# ISS_TOP register map
Vendor: Texas Instruments
Peripheral module from a debugger description file (folder omap5430_ES2_PUBLIC).
Registers are 32-bit, access not given, reset 0x0 unless marked. A register's access mark holds for its fields unless they carry their own. Offsets are as the file gives them; lines under a group give offsets from that group; [hi:lo] are bit positions; {n}, {i} and the like mark numbered series; 'fields as' and 'values as' point back to an identical list; <NAME> marks a mode.

## ISS_TOP
0x00 ISS_HL_REVISION ro reset not defined — IP Revision Identifier (X.Y.R) Used by software to track features, bugs, and compatibility
  [31:0] REVISION — IP Revision
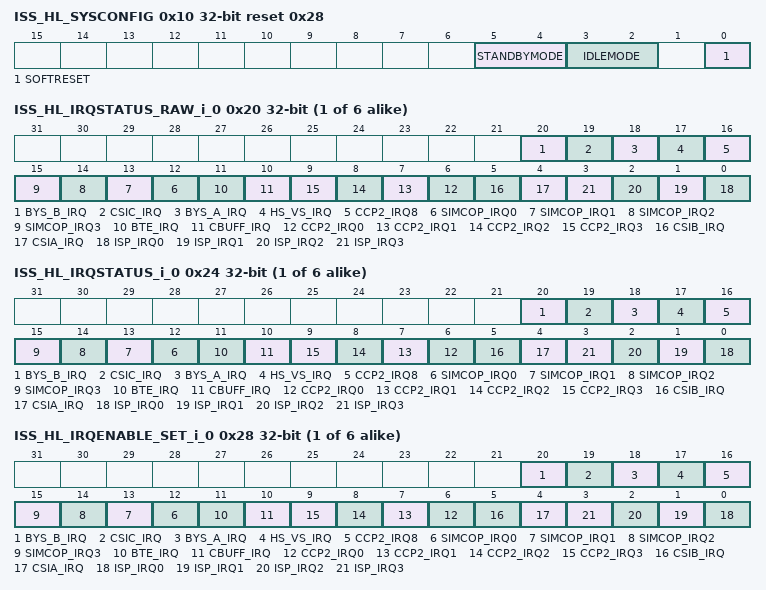
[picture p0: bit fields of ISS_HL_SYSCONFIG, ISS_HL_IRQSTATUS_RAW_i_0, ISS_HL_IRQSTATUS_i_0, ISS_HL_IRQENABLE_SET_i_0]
0x10 ISS_HL_SYSCONFIG access per field reset 0x28 — Clock management configuration
  [5:4] STANDBYMODE rw — Master interface power management, standby/Wait control
    0=FORCE (Force-standby. MStandby is asserted unconditionally.); 1=NO (No-standby. MStandby is never asserted.); 3=SMART2 (Smart-standby Wake up); 2=SMART1 (Smart-standby)
  [3:2] IDLEMODE rw — IDLE protocol configuration
    0=FORCE (Force-idle); 1=NO (No-idle); 3=SMART2 (Smart-idle Wake up); 2=SMART1 (Smart-idle)
  [0] SOFTRESET rw — Software reset.
    0=done (No action); 1=pending (Initiate software reset); 1=pending (Reset (software or other) ongoing); 0=Reset_done,_no_pending_action
{0x20+0x10*i} ISS_HL_IRQSTATUS_RAW_i_{i} access per field (i=0..5) — Per-event raw interrupt status vector, line 0. Raw status is set even if event is not enabled by setting the register.
  [20] BYS_B_IRQ ro — Event generated by BYS_B
    1=pending (Event pending); 0=No event pending
  [19] CSIC_IRQ ro — Event generated by the CSI2_C receiver
    1=pending (Event pending); 0=No event pending
  [18] BYS_A_IRQ ro — Event generated by BYS_A
    1=pending (Event pending); 0=No event pending
  [17] HS_VS_IRQ rw — HS or VS synchronization event. This event is triggered if a rising or falling edge is detected on the HS or VS signal (after the video port mux). The rising or falling edge and the HS or VS signal selection is chosen with the ISS_CTRL[1:0] SYNC_DETECT bit field.
    0=noevent (No action); 1=pending (Set event (debug)); 1=pending (Event pending); 0=No_event_pending
  [16] CCP2_IRQ8 ro — Event generated by the CCP2 receiver
    1=pending (Event pending); 0=No event pending
  [n+12] SIMCOP_IRQ{n} ro (n=0..3) — Event generated by SIMCOP
    1=pending (Event pending); 0=No event pending
  [11] BTE_IRQ ro — Event generated by the burst translation engine
    1=pending (Event pending); 0=No event pending
  [10] CBUFF_IRQ ro — Event generated by the circular buffer
    1=pending (Event pending); 0=No event pending
  [n+6] CCP2_IRQ{n} ro (n=0..3) — Event generated by the CCP2 receiver
    1=pending (Event pending); 0=No event pending
  [5] CSIB_IRQ ro — Event generated by the CSI2_B receiver
    1=pending (Event pending); 0=No event pending
  [4] CSIA_IRQ ro — Event generated by the CSI2_A receiver
    1=pending (Event pending); 0=No event pending
  [n] ISP_IRQ{n} ro (n=0..3) — Combined interrupt event provided by the ISP.
    1=pending (Event pending); 0=No event pending
{0x24+0x10*i} ISS_HL_IRQSTATUS_i_{i} (i=0..5) — Per-event 'enabled' interrupt status vector, line 0. Enabled status is not set unless event is enabled by setting the register.
  [20] BYS_B_IRQ ro — Event generated by BYS_B
    1=pending (Event pending); 0=noevent (No (enabled) event pending)
  [19] CSIC_IRQ ro — Event generated by the CSI2_C receiver
    values as BYS_B_IRQ
  [18] BYS_A_IRQ ro — Event generated by BYS_A
    values as BYS_B_IRQ
  [17] HS_VS_IRQ — HS or VS synchronization event. This event is triggered if a rising or falling edge is detected on the HS or VS signal (after the video port mux). The rising or falling edge and the HS or VS signal selection is chosen with the ISS_CTRL[1:0] SYNC_DETECT bit field. (access RW W1toSet)
    0=noevent (No action); 1=pending (Clear (raw) event); 1=pending (Event pending); 0=No_(enabled)_event_pending
  [16] CCP2_IRQ8 ro — Event generated by the CCP2 receiver
    values as BYS_B_IRQ
  [n+12] SIMCOP_IRQ{n} ro (n=0..3) — Event generated by SIMCOP
    values as BYS_B_IRQ
  [11] BTE_IRQ ro — Event generated by the burst translation engine
    values as BYS_B_IRQ
  [10] CBUFF_IRQ ro — Event generated by the circular buffer
    values as BYS_B_IRQ
  [n+6] CCP2_IRQ{n} ro (n=0..3) — Event generated by the CCP2 receiver
    values as BYS_B_IRQ
  [5] CSIB_IRQ ro — Event generated by the CSI2_B receiver
    values as BYS_B_IRQ
  [4] CSIA_IRQ ro — Event generated by the CSI2_A receiver
    values as BYS_B_IRQ
  [n] ISP_IRQ{n} ro (n=0..3) — Combined interrupt event provided by the ISP.
    values as BYS_B_IRQ
{0x28+0x10*i} ISS_HL_IRQENABLE_SET_i_{i} (i=0..5) — Per-event interrupt enable bit vector. Write 1 to set (enable interrupt). Readout equal to corresponding register bit.
  [20] BYS_B_IRQ — Event generated by BYS_B (access RW W1toSet)
    0=disabled (No action); 1=enabled (Enable interrupt); 1=enabled (Interrupt enabled); 0=Interrupt_disabled_(masked)
  [19] CSIC_IRQ — Event generated by the CSI2_C receiver (access RW W1toSet)
    values as BYS_B_IRQ
  [18] BYS_A_IRQ — Event generated by BYS_A (access RW W1toSet)
    values as BYS_B_IRQ
  [17] HS_VS_IRQ — HS or VS synchronization event. This event is triggered if a rising or falling edge is detected on the HS or VS signal (after the video port mux). The rising or falling edge and the HS or VS signal selection is chosen with the ISS_CTRL[1:0] SYNC_DETECT bit field. (access RW W1toSet)
    values as BYS_B_IRQ
  [16] CCP2_IRQ8 — Event generated by the CCP2 receiver (access RW W1toSet)
    0=disabled (No action Write 0x1: Enable interrupt); 1=disabled (Interrupt enabled Read 0x0: Interrupt disabled (masked))
  [n+12] SIMCOP_IRQ{n} (n=0..3) — Event generated by SIMCOP (access RW W1toSet)
    values as BYS_B_IRQ
  [11] BTE_IRQ — Event generated by the burst translation engine (access RW W1toSet)
    values as BYS_B_IRQ
  [10] CBUFF_IRQ — Event generated by the circular buffer (access RW W1toSet)
    values as BYS_B_IRQ
  [n+6] CCP2_IRQ{n} (n=0..3) — Event generated by the CCP2 receiver (access RW W1toSet)
    values as BYS_B_IRQ
  [5] CSIB_IRQ — Event generated by the CSI2_B receiver (access RW W1toSet)
    values as BYS_B_IRQ
  [4] CSIA_IRQ — Event generated by the CSI2_A receiver (access RW W1toSet)
    values as BYS_B_IRQ
  [n] ISP_IRQ{n} (n=0..3) — Combined interrupt event provided by the ISP. (access RW W1toSet)
    values as BYS_B_IRQ
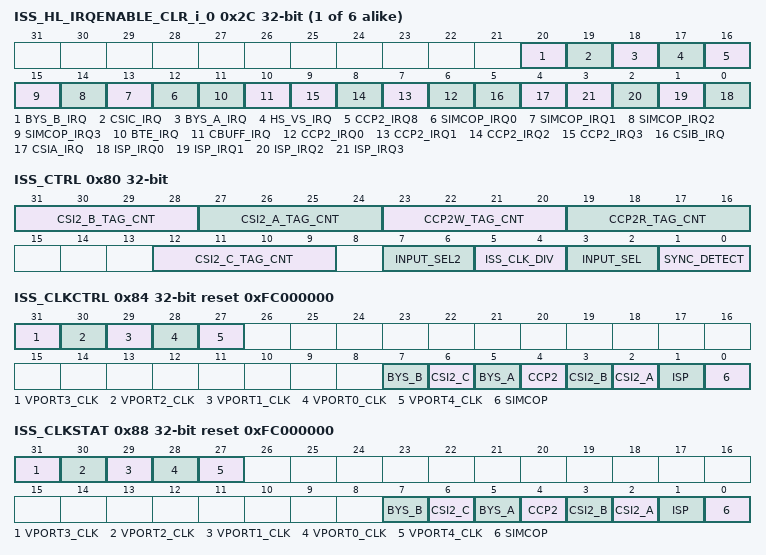
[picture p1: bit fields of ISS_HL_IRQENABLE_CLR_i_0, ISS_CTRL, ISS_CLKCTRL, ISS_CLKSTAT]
{0x2C+0x10*i} ISS_HL_IRQENABLE_CLR_i_{i} (i=0..5) — Per-event interrupt enable bit vector Write 1 to clear (disable interrupt). Readout equal to corresponding register bit.
  [20] BYS_B_IRQ — Event generated by BYS_B (access RW W1toClr)
    0=disabled (No action); 1=enabled (Disable interrupt); 1=enabled (Interrupt enabled); 0=Interrupt_disabled_(masked)
  [19] CSIC_IRQ — Event generated by the CSI2_C receiver (access RW W1toClr)
    values as BYS_B_IRQ
  [18] BYS_A_IRQ — Event generated by BYS_A (access RW W1toClr)
    values as BYS_B_IRQ
  [17] HS_VS_IRQ — HS or VS synchronization event. This event is triggered if a rising or falling edge is detected on the HS or VS signal (after the video port mux). The rising or falling edge and the HS or VS signal selection is chosen with the ISS_CTRL[1:0] SYNC_DETECT bit field. (access RW W1toClr)
    values as BYS_B_IRQ
  [16] CCP2_IRQ8 — Event generated by the CCP2 receiver (access RW W1toSet)
    values as ISS_HL_IRQENABLE_SET_i_0.CCP2_IRQ8
  [n+12] SIMCOP_IRQ{n} (n=0..3) — Event generated by SIMCOP (access RW W1toClr)
    values as BYS_B_IRQ
  [11] BTE_IRQ — Event generated by the BTE (access RW W1toClr)
    values as BYS_B_IRQ
  [10] CBUFF_IRQ — Event generated by the CBUFF (access RW W1toClr)
    values as BYS_B_IRQ
  [n+6] CCP2_IRQ{n} (n=0..3) — Event generated by the CCP2 receiver (access RW W1toClr)
    values as BYS_B_IRQ
  [5] CSIB_IRQ — Event generated by the CSI2_B receiver (access RW W1toClr)
    values as BYS_B_IRQ
  [4] CSIA_IRQ — Event generated by the CSI2_C receiver (access RW W1toClr)
    values as BYS_B_IRQ
  [n] ISP_IRQ{n} (n=0..3) — Combined interrupt event provided by the ISP. (access RW W1toClr)
    values as BYS_B_IRQ
0x80 ISS_CTRL access per field — ISS control register
  [31:28] CSI2_B_TAG_CNT rw — Defines the maximum number of tags that could be used by the CSI2_B write bridge. Note: Tag count must be set to 16 for best performance.
  [27:24] CSI2_A_TAG_CNT rw — Defines the maximum number of tags that could be used by the CSI2_A write bridge. Note: Tag count must be set to 16 for best performance.
  [23:20] CCP2W_TAG_CNT rw — Defines the maximum number of tags that could be used by the CCP2 write bridge Note: Tag count must be set to 16 for best performance.
  [19:16] CCP2R_TAG_CNT rw — Defines the maximum number of tags that could be used by the CCP2 read bridge Note: Tag count must be set to 16 for best performance.
  [12:9] CSI2_C_TAG_CNT rw — Defines the maximum number of tags that could be used by the CSI2_C write bridge.
  [7:6] INPUT_SEL2 rw — Selects ISP input
    0=NONE (Input selected by the [3:2] INPUT_SEL register bit-field in this register); 1=CSI2_C; 3=RSV (reserved); 2=CSI3_A (reserved)
  [5:4] ISS_CLK_DIV rw — ISS functional clock division CLK refers to the input clock provided to the ISS. FCLK is the functional clock provided to ISS top level and submodules. CFGCLK is the clock used for the configuration network.
    0=NONE (FCLK=CLK CFGCLK=CLK/2); 1=DIV2 (FCLK=CLK/2 CFGCLK=CLK/4); 3=RSZ (Reserved); 2=DIV4 (FCLK=CLK/4 CFGCLK=CLK/8)
  [3:2] INPUT_SEL rw — Selects ISP input
    0=CSI2_A; 1=CSI2_B; 2=CCP2; 3=PAR (Parallel interface)
  [1:0] SYNC_DETECT rw — Chooses among rising and falling edge for the HS_VS_IRQ synchronization event
    0=HSF (HS falling edge); 1=HSR (HS raising edge); 3=VSR (VS raising edge); 2=VSF (VS falling edge)
0x84 ISS_CLKCTRL access per field reset 0xFC000000 — ISS clock control register. Use to enable/disable the interface and functional clock of ISS submodules.
  [31] VPORT3_CLK rw — Enables the pixel clock from the parallel interface
    0=zero (Disabled); 1=one (Enabled)
  [30] VPORT2_CLK rw — Enables the pixel clock from the CCP2 protocol engine
    0=zero (Disabled); 1=one (Enabled)
  [29] VPORT1_CLK rw — Enables the pixel clock from the CSI2_B protocol engine
    0=zero (Disabled); 1=one (Enabled)
  [28] VPORT0_CLK rw — Enables the pixel clock from the CSI2_A protocol engine
    0=zero (Disabled); 1=one (Enabled)
  [27] VPORT4_CLK rw — Enables the pixel clock from the CSI2_C protocol engine
    0=zero (Disabled); 1=one (Enabled)
  [7] BYS_B wo
    0=OFF (Request shutdown of the sub-module. No effect if the sub-module clock is already off.); 1=ON (Request enable of the sub-module. No effect if the sub-module clock is already on.)
  [6] CSI2_C wo
    values as BYS_B
  [5] BYS_A wo
    values as BYS_B
  [4] CCP2 wo
    0=OFF (Request shutdown of the submodule. No effect if the submodule clock is already off.); 1=ON (Request enable of the submodule. No effect if the submodule clock is already on.)
  [3] CSI2_B wo
    values as CCP2
  [2] CSI2_A wo
    values as CCP2
  [1] ISP wo
    values as CCP2
  [0] SIMCOP wo
    values as CCP2
0x88 ISS_CLKSTAT ro reset 0xFC000000 — ISS clock status register.
  [31] VPORT3_CLK — Status of the pixel clock from the parallel interface
    1=one (Enabled); 0=zero (Disabled)
  [30] VPORT2_CLK — Status of the pixel clock from the CCP2 protocol engine
    1=one (Enabled); 0=zero (Disabled)
  [29] VPORT1_CLK — Status of the pixel clock from the CSI2_B protocol engine
    1=one (Enabled); 0=zero (Disabled)
  [28] VPORT0_CLK — Status of the pixel clock from the CSI2_A protocol engine
    1=one (Enabled); 0=zero (Disabled)
  [27] VPORT4_CLK — Status of the pixel clock from the CSI2_C protocol engine
    1=one (Enabled); 0=zero (Disabled)
  [7] BYS_B
    1=ON (The sub-module is on); 0=OFF (The sub-module is off)
  [6] CSI2_C
    1=ON (The sub-module is on); 0=OFF (The sub-module is off)
  [5] BYS_A
    1=ON (The sub-module is on); 0=OFF (The sub-module is off)
  [4] CCP2
    1=ON (The submodule is on.); 0=OFF (The submodule is off.)
  [3] CSI2_B
    1=ON (The submodule is on.); 0=OFF (The submodule is off.)
  [2] CSI2_A
    1=ON (The submodule is on.); 0=OFF (The submodule is off.)
  [1] ISP
    1=ON (The submodule is on.); 0=OFF (The submodule is off.)
  [0] SIMCOP
    1=ON (The submodule is on.); 0=OFF (The submodule is off.)
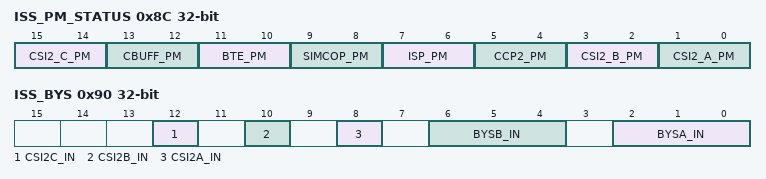
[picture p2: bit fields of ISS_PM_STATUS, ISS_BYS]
0x8C ISS_PM_STATUS ro — ISS power manager status register. Software could know what modules are in functional or STANDBY/IDLE state. This feature could be particularly useful to debug when ISS does not go into STANDBY mode
  [15:14] CSI2_C_PM — Power status of the CSI2_C module
    2=FUNC (Functional); 1=TRANS (Transition); 0=STANDBY
  [13:12] CBUFF_PM — Power status of the CBUFF.
    2=FUNC (Functional); 1=TRANS (Transition); 0=IDLE
  [11:10] BTE_PM — Power status of the BTE.
    2=FUNC (Functional); 1=TRANS (Transition); 0=IDLE
  [9:8] SIMCOP_PM — Power status of the SIMCOP.
    2=FUNC (Functional); 1=TRANS (Transition); 0=STANDBY
  [7:6] ISP_PM — Power status of the ISP.
    2=FUNC (Functional); 1=TRANS (Transition); 0=STANDBY
  [5:4] CCP2_PM — Power status of the CCP2.
    2=FUNC (Functional); 1=TRANS (Transition); 0=STANDBY
  [3:2] CSI2_B_PM — Power status of the CSI2_B module
    2=FUNC (Functional); 1=TRANS (Transition); 0=STANDBY
  [1:0] CSI2_A_PM — Power status of the CSI2_A module
    2=FUNC (Functional); 1=TRANS (Transition); 0=STANDBY
0x90 ISS_BYS access per field — BYS IO selection
  [12] CSI2C_IN rw — Selects input of CSI2_C BYS input
    0=A (BYS_A); 1=B (BYS_B)
  [10] CSI2B_IN rw — Selects input of CSI2_B BYS input
    0=A (BYS_A); 1=B (BYS_B)
  [8] CSI2A_IN rw — Selects input of CSI2_A BYS input
    0=A (BYS_A); 1=B (BYS_B)
  [6:4] BYSB_IN rw — Selects BYS_B input
    0=NONE (Disabled); 1=CSI2_A; 3=CSI2_C; 4=CSI3_A (Reserved); 2=CSI2_B
  [2:0] BYSA_IN rw — Selects BYS_A input
    values as BYSB_IN
